VERSION ""

NS_ :

BS_:

BU_: VCU BMS Motor

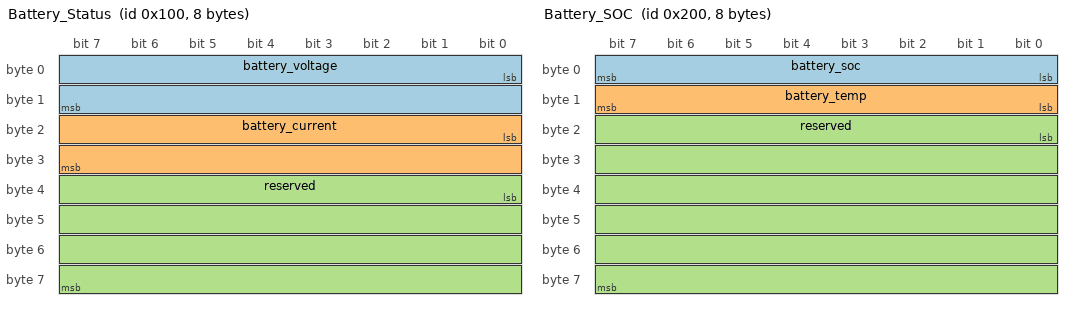
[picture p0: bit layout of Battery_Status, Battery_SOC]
BO_ 256 Battery_Status: 8 BMS
 SG_ battery_voltage : 0|16@1+ (0.1,0) [0|6553.5] "V" VCU
 SG_ battery_current : 16|16@1- (0.1,0) [-3276.8|3276.7] "A" VCU
 SG_ reserved : 32|32@1+ (1,0) [0|0] "" VCU

BO_ 512 Battery_SOC: 8 BMS
 SG_ battery_soc : 0|8@1+ (1,0) [0|100] "%" VCU
 SG_ battery_temp : 8|8@1+ (1,-40) [-40|215] "C" VCU
 SG_ reserved : 16|48@1+ (1,0) [0|0] "" VCU

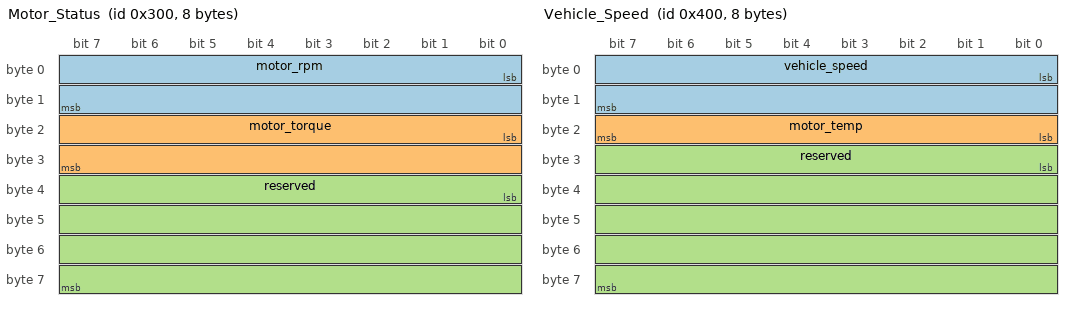
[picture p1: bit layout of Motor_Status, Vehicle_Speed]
BO_ 768 Motor_Status: 8 Motor
 SG_ motor_rpm : 0|16@1+ (1,0) [0|65535] "rpm" VCU
 SG_ motor_torque : 16|16@1+ (0.1,0) [0|6553.5] "Nm" VCU
 SG_ reserved : 32|32@1+ (1,0) [0|0] "" VCU

BO_ 1024 Vehicle_Speed: 8 VCU
 SG_ vehicle_speed : 0|16@1+ (0.01,0) [0|655.35] "km/h" Motor
 SG_ motor_temp : 16|8@1+ (1,-40) [-40|215] "C" Motor
 SG_ reserved : 24|40@1+ (1,0) [0|0] "" VCU

CM_ SG_ 256 battery_voltage "Battery pack voltage";
CM_ SG_ 256 battery_current "Battery pack current (negative = discharge)";
CM_ SG_ 512 battery_soc "Battery state of charge";
CM_ SG_ 512 battery_temp "Battery pack temperature";
CM_ SG_ 768 motor_rpm "Motor speed in RPM";
CM_ SG_ 768 motor_torque "Motor torque";
CM_ SG_ 1024 vehicle_speed "Vehicle speed";
CM_ SG_ 1024 motor_temp "Motor temperature";
